# A64 register map
Vendor: Allwinner; Series: A64; File version: 0.1
CPU: CA53 0, little endian, MPU, no FPU, 0 interrupt priority bits
Registers are 32-bit, read-write, reset 0x0 unless marked. A register's access mark holds for its fields unless they carry their own. Offsets are from the block's base; [hi:lo] are bit positions; {n}, {i} and the like mark numbered series; 'fields as' and 'values as' point back to an identical list.

## AC (part 1 of 2)
Base 0x01C22C00
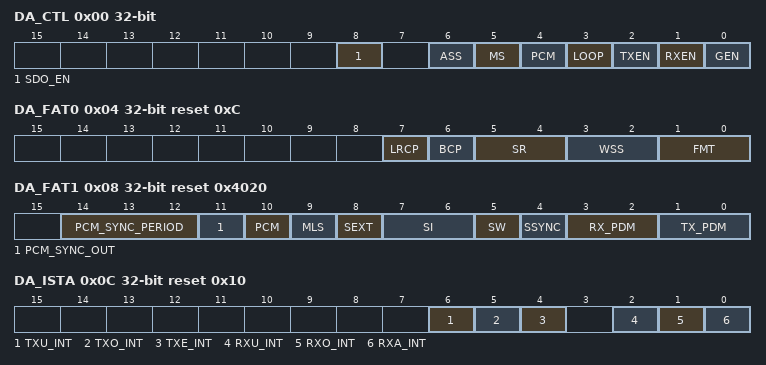
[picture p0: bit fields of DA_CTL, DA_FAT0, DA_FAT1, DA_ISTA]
0x00 DA_CTL — Digital Audio Control Register
  [8] SDO_EN — 0: Disable 1: Enable
    0=Disable; 1=Enable
  [6] ASS — Audio sample select when TX FIFO under run 0: Sending zero 1: Sending last audio sample
    0=Sending_zero; 1=Sending last audio sample
  [5] MS — Master Slave Select 0: Master 1: Slave
    0=Master; 1=Slave
  [4] PCM — 0: I2S Interface 1: PCM Interface
    0=I2S (I2S Interface); 1=PCM (PCM Interface)
  [3] LOOP — Loop back test 0: Normal mode 1: Loop back test When set `1`, connecting the SDO with the SDI in Master mode.
    0=Normal_mode; 1=Loop back test When set `1`, connecting the SDO with the SDI in Master mode
  [2] TXEN — Transmitter Block Enable 0: Disable 1: Enable
    0=Disable; 1=Enable
  [1] RXEN — Receiver Block Enable 0: Disable 1: Enable
    0=Disable; 1=Enable
  [0] GEN — Globe Enable A disable on this bit overrides any other block or channel enables and flushes all FIFOs. 0: Disable 1: Enable
    0=Disable; 1=Enable
0x04 DA_FAT0 reset 0xC — Digital Audio Format Register 0
  [7] LRCP — Left/ Right Clock Parity 0: Normal 1: Inverted In DSP/ PCM mode 0: MSB is available on 2nd BCLK rising edge after LRC rising edge 1: MSB is available on 1st BCLK rising edge after LRC rising edge
  [6] BCP — BCLK Parity 0: Normal 1: Inverted
    0=Normal; 1=Inverted
  [5:4] SR — Sample Resolution 00: 16-bits 01: 20-bits 10: 24-bits 11: Reserved
    0=_16_bits; 1=_20_bits; 2=_24_bits
  [3:2] WSS — Word Select Size 00: 16 BCLK 01: 20 BCLK 10: 24 BCLK 11: 32 BCLK
    0=16 BCLK; 1=20 BCLK; 2=24 BCLK; 3=32 BCLK
  [1:0] FMT — Serial Data Format 00: Standard I2S Format 01: Left Justified Format 10: Right Justified Format 11: Reserved
    0=Standard I2S Format; 1=Left Justified Format; 2=Right Justified Format
0x08 DA_FAT1 reset 0x4020 — Digital Audio Format Register 1
  [14:12] PCM_SYNC_PERIOD — PCM SYNC Period Clock Number 000: 16 BCLK period 001: 32 BCLK period 010: 64 BCLK period 011: 128 BCLK period 100: 256 BCLK period Others : Reserved
    0=16 BCLK period; 1=32 BCLK period; 2=64 BCLK period; 3=128 BCLK period; 4=256 BCLK period Others : Reserved
  [11] PCM_SYNC_OUT — PCM Sync Out 0: Enable PCM_SYNC output in Master mode 1: Suppress PCM_SYNC whilst keeping PCM_CLK running. Some Codec utilize this to enter a low power state.
    0=Enable PCM_SYNC output in Master mode; 1=Suppress PCM_SYNC whilst keeping PCM_CLK running. Some Codec utilize this to enter a low power state.
  [10] PCM — Out Mute Write 1 force PCM_OUT to 0
  [9] MLS — MSB / LSB First Select 0: MSB First 1: LSB First
    0=MSB (MSB First); 1=LSB (LSB First)
  [8] SEXT — Sign Extend (only for 16 bits slot) 0: Zeros or audio gain padding at LSB position 1: Sign extension at MSB position When writing the bit is 0, the unused bits are audio gain for 13-bit linear sample and zeros padding for 8-bit companding sample. When writing the bit is 1, the unused bits are both sign extension.
    0=Zeros or audio gain padding at LSB position; 1=Sign extension at MSB position When writing the bit is 0, the unused bits are audio gain for 13-bit linear sample and zeros padding for 8-bit companding sample. When writing the bit is 1, the unused bits are both sign extension.
  [7:6] SI — Slot Index 00: the 1st slot 01: the 2nd slot 10: the 3rd slot 11: the 4th slot
    0=_1st (the 1st slot); 1=_2nd (the 2nd slot); 2=_3rd (the 3rd slot); 3=_4th (the 4th slot)
  [5] SW — Slot Width 0: 8 clocks width 1: 16 clocks width Notes: For A-law or u-law PCM sample, if this bit is set to 1, eight zero bits are following with PCM sample.
    0=8 clocks width; 1=16 clocks width Notes: For A-law or u-law PCM sample, if this bit is set to 1, eight zero bits are following with PCM sample
  [4] SSYNC — Short Sync Select 0: Long Frame Sync 1: Short Frame Sync It should be set `1` for 8 clocks width slot.
    0=Long Frame Sync; 1=Short Frame Sync It should be set `1` for 8 clocks width slot
  [3:2] RX_PDM — PCM Data Mode 00: 16-bits Linear PCM 01: 8-bits Linear PCM 10: 8-bits u-law 11: 8-bits A-law
    0=16-bits Linear PCM; 1=8-bits Linear PCM; 2=_8_bits_ulaw; 3=_8_bits_Alaw
  [1:0] TX_PDM — PCM Data Mode 00: 16-bits Linear PCM 01: 8-bits Linear PCM 10: 8-bits u-law 11: 8-bits A-law
    values as RX_PDM
0x0C DA_ISTA reset 0x10 — Digital Audio Interrupt Status Register
  [6] TXU_INT — TX FIFO Under run Pending Interrupt 0: No Pending Interrupt 1: FIFO Under run Pending Interrupt
    0=No Pending Interrupt; 1=FIFO (FIFO Under run Pending Interrupt)
  [5] TXO_INT — TX FIFO Overrun Pending Interrupt 0: No Pending Interrupt 1: FIFO Overrun Pending Interrupt Write `1` to clear this interrupt
    0=No Pending Interrupt; 1=FIFO (FIFO Overrun Pending Interrupt Write `1` to clear this interrupt)
  [4] TXE_INT — TX FIFO Empty Pending Interrupt 0: No Pending IRQ 1: FIFO Empty Pending Interrupt Write `1` to clear this interrupt or automatic clear if interrupt condition fails.
    0=No Pending IRQ; 1=FIFO (FIFO Empty Pending Interrupt Write `1` to clear this interrupt or automatic clear if interrupt condition fails.)
  [2] RXU_INT — RX FIFO Under run Pending Interrupt 0: No Pending Interrupt 1:FIFO Under run Pending Interrupt Write 1 to clear this interrupt
    0=No Pending Interrupt 1:FIFO Under run Pending Interrupt Write 1 to clear this interrupt
  [1] RXO_INT — RX FIFO Overrun Pending Interrupt 0: No Pending IRQ 1: FIFO Overrun Pending IRQ Write `1` to clear this interrupt
    0=No Pending IRQ; 1=FIFO (FIFO Overrun Pending IRQ Write `1` to clear this interrupt)
  [0] RXA_INT — RX FIFO Data Available Pending Interrupt 0: No Pending IRQ 1: Data Available Pending IRQ Write `1` to clear this interrupt or automatic clear if interrupt condition fails.
    0=No Pending IRQ; 1=Data Available Pending IRQ Write `1` to clear this interrupt or automatic clear if interrupt condition fails
0x10 DA_RXFIFO — Digital Audio RX FIFO Register
  [31:0] RX_DATA ro — RX Sample Host can get one sample by reading this register. The left channel sample data is first and then the right channel sample.
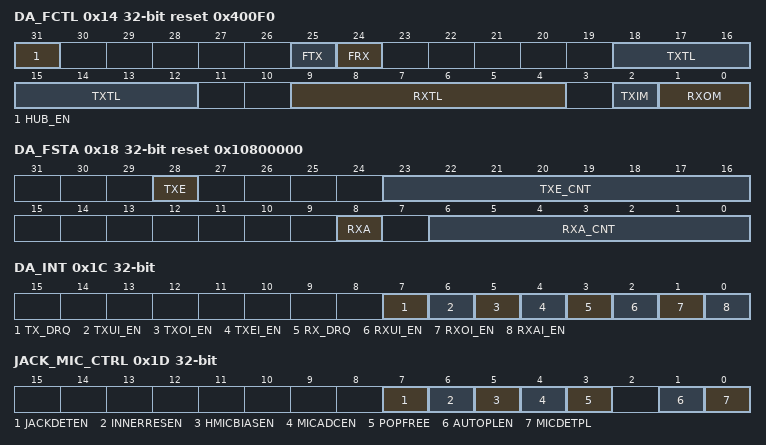
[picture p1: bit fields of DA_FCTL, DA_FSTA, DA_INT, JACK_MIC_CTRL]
0x14 DA_FCTL reset 0x400F0 — Digital Audio FIFO Control Register
  [31] HUB_EN — Audio Hub Enable 0: Disable 1: Enable
    0=Disable; 1=Enable
  [25] FTX — Write `1` to flush TX FIFO, self clear to `0`.
  [24] FRX — Write `1` to flush RX FIFO, self clear to `0`.
  [18:12] TXTL — TX FIFO Empty Trigger Level Interrupt and DMA request trigger level for TXFIFO normal condition Trigger Level = TXTL
  [9:4] RXTL — RX FIFO Trigger Level Interrupt and DMA request trigger level for RXFIFO normal condition Trigger Level = RXTL + 1
  [2] TXIM — TX FIFO Input Mode (Mode 0, 1) 0: Valid data at the MSB of TXFIFO register 1: Valid data at the LSB of TXFIFO register Example for 20-bits transmitted audio sample: Mode 0: FIFO_I[23:0] = {TXFIFO[31:12], 4`h0} Mode 1: FIFO_I[23:0] = {TXFIFO[19:0], 4`h0}
    0=Valid data at the MSB of TXFIFO register; 1=Valid data at the LSB of TXFIFO register Example for 20-bits transmitted audio sample: Mode 0: FIFO_I[23:0] = {TXFIFO[31:12], 4`h0} Mode 1: FIFO_I[23:0] = {TXFIFO[19:0], 4`h0}
  [1:0] RXOM — RX FIFO Output Mode (Mode 0, 1, 2, 3) 00: Expanding `0` at LSB of DA_RXFIFO register. 01: Expanding received sample sign bit at MSB of DA_RXFIFO register. 10: Truncating received samples at high half-word of DA_RXFIFO register and low half-word of DA_RXFIFO register is filled by `0`. 11: Truncating received samples at low half-word of DA_RXFIFO register and high half-word of DA_RXFIFO register is expanded by its sign bit. Example for 20-bits received audio sample: Mode 0: RXFIFO[31:0] = {FIFO_O[19:0], 12`h0} Mode 1: RXFIFO[31:0] = {12{FIFO_O[19]}, FIFO_O[19:0]} Mode 2: RXFIFO[31:0] = {FIFO_O[19:4], 16`h0} Mode 3: RXFIFO[31:0] = {16{FIFO_O[19], FIFO_O[19:4]}
    0=Expanding `0` at LSB of DA_RXFIFO register; 1=Expanding received sample sign bit at MSB of DA_RXFIFO register; 2=Truncating received samples at high half-word of DA_RXFIFO register and low half-word of DA_RXFIFO register is filled by `0`; 3=Truncating received samples at low half-word of DA_RXFIFO register and high half-word of DA_RXFIFO register is expanded by its sign bit. Example for 20-bits received audio sample: Mode 0: RXFIFO[31:0] = {FIFO_O[19:0], 12`h0} Mode 1: RXFIFO[31:0] = {12{FIFO_O[19]}, FIFO_O[19:0]} Mode 2: RXFIFO[31:0] = {FIFO_O[19:4], 16`h0} Mode 3: RXFIFO[31:0] = {16{FIFO_O[19], FIFO_O[19:4]}
0x18 DA_FSTA reset 0x10800000 — Digital Audio FIFO Status Register
  [28] TXE ro — TX FIFO Empty 0: No room for new sample in TX FIFO 1: More than one room for new sample in TX FIFO (>= 1 word)
    0=No room for new sample in TX FIFO; 1=More than one room for new sample in TX FIFO (>= 1 word)
  [23:16] TXE_CNT ro — TX FIFO Empty Space Word Counter
  [8] RXA ro — RX FIFO Available 0: No available data in RX FIFO 1: More than one sample in RX FIFO (>= 1 word)
    0=No available data in RX FIFO; 1=More than one sample in RX FIFO (>= 1 word)
  [6:0] RXA_CNT ro — RX FIFO Available Sample Word Counter
0x1C DA_INT — Digital Audio Interrupt Control Register
  [7] TX_DRQ — TX FIFO Empty DRQ Enable 0: Disable 1: Enable
    0=Disable; 1=Enable
  [6] TXUI_EN — TX FIFO Under run Interrupt Enable 0: Disable 1: Enable
    0=Disable; 1=Enable
  [5] TXOI_EN — TX FIFO Overrun Interrupt Enable 0: Disable 1: Enable When set to `1`, an interrupt happens when writing new audio data if TX FIFO is full.
    0=Disable; 1=Enable When set to `1`, an interrupt happens when writing new audio data if TX FIFO is full
  [4] TXEI_EN — TX FIFO Empty Interrupt Enable 0: Disable 1: Enable
    0=Disable; 1=Enable
  [3] RX_DRQ — RX FIFO Data Available DRQ Enable 0: Disable 1: Enable When set to `1`, RXFIFO DMA Request line is asserted if Data is available in RX FIFO.
    0=Disable; 1=Enable When set to `1`, RXFIFO DMA Request line is asserted if Data is available in RX FIFO
  [2] RXUI_EN — RX FIFO Under run Interrupt Enable 0: Disable 1: Enable
    0=Disable; 1=Enable
  [1] RXOI_EN — RX FIFO Overrun Interrupt Enable 0: Disable 1: Enable
    0=Disable; 1=Enable
  [0] RXAI_EN — RX FIFO Data Available Interrupt Enable 0: Disable 1: Enable
    0=Disable; 1=Enable
0x1D JACK_MIC_CTRL
  [7] JACKDETEN — Jack detect enable 0: disable, 1: enable
    0=disable, 1: enable
  [6] INNERRESEN — Inner 2.2k resistor between hbias and micdet enable 0: disable, 1: enable
    0=disable, 1: enable
  [5] HMICBIASEN — Handset Microphone Bias enable 0: disable, 1: enable
    0=disable, 1: enable
  [4] MICADCEN — Microphone detect ADC enable 0: disable, 1: enable
    0=disable, 1: enable
  [3] POPFREE — When this bit is 0, HBIAS MICADC is controlled by registor
  [1] AUTOPLEN — Enable the function to auto pull low micdet when jack removal 0: disable, 1: enable
    0=disable, 1: enable
  [0] MICDETPL — When this bit is 1and AUTOPLEN is 0, the micdet is pull to gnd
0x20 DA_TXFIFO — Digital Audio TX FIFO Register
  [31:0] TX_DATA wo — Transmitting left, right channel sample data should be written this register one by one. The left channel sample data is first and then the right channel sample.
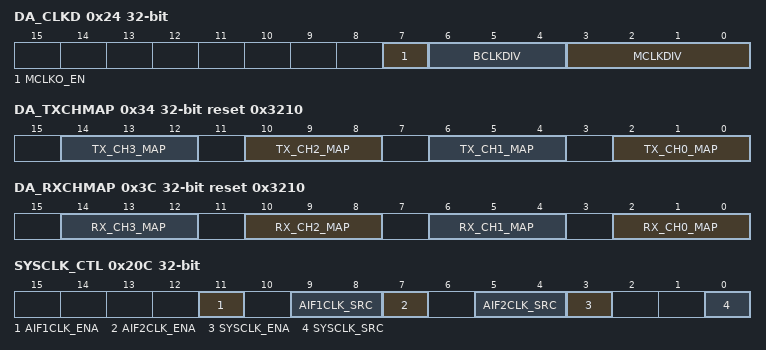
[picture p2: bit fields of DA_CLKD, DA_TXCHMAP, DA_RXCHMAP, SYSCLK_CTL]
0x24 DA_CLKD — Digital Audio Clock Divide Register
  [7] MCLKO_EN — 0: Disable MCLK Output 1: Enable MCLK Output Notes: Whether in Slave or Master mode, when this bit is set to 1, MCLK should be output.
    0=Disable MCLK Output; 1=Enable MCLK Output Notes: Whether in Slave or Master mode, when this bit is set to 1, MCLK should be output
  [6:4] BCLKDIV — BCLK Divide Ratio from MCLK 000: Divide by 2 (BCLK = MCLK/2) 001: Divide by 4 010: Divide by 6 011: Divide by 8 100: Divide by 12 101: Divide by 16 110: Divide by 32 111: Divide by 64
    0=Divide by 2 (BCLK = MCLK/2); 1=Divide_by_4; 2=Divide_by_6; 3=Divide_by_8; 4=Divide_by_12; 5=Divide_by_16; 6=Divide_by_32; 7=Divide_by_64
  [3:0] MCLKDIV — MCLK Divide Ratio from Audio PLL Output 0000: Divide by 1 0001: Divide by 2 0010: Divide by 4 0011: Divide by 6 0100: Divide by 8 0101: Divide by 12 0110: Divide by 16 0111: Divide by 24 1000: Divide by 32 1001: Divide by 48 1010: Divide by 64 Others : Reserved
    0=Divide_by_1; 1=Divide_by_2; 2=Divide_by_4; 3=Divide_by_6; 4=Divide_by_8; 5=Divide_by_12; 6=Divide_by_16; 7=Divide_by_24; 8=Divide_by_32; 9=Divide_by_48; 10=Divide by 64 Others : Reserved
0x28 DA_TXCNT — Digital Audio RX Sample Counter Register
  [31:0] TX_CNT — TX Sample Counter The audio sample number of sending into TXFIFO. When one sample is put into TXFIFO by DMA or by host IO, the TX sample counter register increases by one. The TX sample counter register can be set to any initial valve at any time. After been updated by the initial value, the counter register should count on base of this initial value.
0x2C DA_RXCNT — Digital Audio TX Sample Counter Register
  [31:0] RX_CNT — RX Sample Counter The audio sample number of writing into RXFIFO. When one sample is written by I2S_AP Engine, the RX sample counter register increases by one. The RX sample counter register can be set to any initial valve at any time. After been updated by the initial value, the counter register should count on base of this initial value.
0x30 DA_TXCHSEL reset 0x1 — Digital Audio TX Channel Select register
  [2:0] TX_CHSEL — TX Channel Select 0: 1-ch 1: 2-ch 2: 3-ch 3: 4-ch
    2=_3_minus_ch (3-ch); 3=_4_minus_ch (4-ch)
0x34 DA_TXCHMAP reset 0x3210 — Digital Audio TX Channel Mapping Register
  [all] fields
    {v}=_{v+1}_sample (v=0..3)
  [4n+2:4n] TX_CH{n}_MAP (n=0..3) — TX Channel{n} Mapping 000: 1 sample 001: 2 sample 010: 3 sample 011: 4 sample 1xx: Reserved
0x38 DA_RXCHSEL reset 0x1 — Digital Audio RX Channel Select register
  [2:0] RX_CHSEL — RX Channel Select 0: 1-ch 1: 2-ch 2: 3-ch 3: 4-ch Others: Reserved
    2=_3_minus_ch (3-ch); 3=_4_minus_ch (4-ch Others: Reserved)
0x3C DA_RXCHMAP reset 0x3210 — Digital Audio RX Channel Mapping Register
  [all] fields
    {v}=_{v+1}_sample (v=0..3)
  [4n+2:4n] RX_CH{n}_MAP (n=0..3) — RX Channel{n} Mapping 000: 1 sample 001: 2 sample 010: 3 sample 011: 4 sample 1xx: Reserved
0x200 Codec_RST reset not defined — Chip Soft Reset Register
0x20C SYSCLK_CTL — System Clock Control Register
  [11] AIF1CLK_ENA — AIF1CLK Enable 0: Disable 1: Enable
    0=Disable; 1=Enable
  [9:8] AIF1CLK_SRC — AIF1CLK Source Select 00: MLCK1 01: Reserved 1X: pll2_1x
    0=MLCK1; 2=pll2_1x
  [7] AIF2CLK_ENA — AIF2CLK Enable 0: Disable 1: Enable
    0=Disable; 1=Enable
  [5:4] AIF2CLK_SRC — AIF2CLK Source Select 00: MLCK1 01: Reserved 1X: pll2_1x
    0=MLCK1; 2=pll2_1x
  [3] SYSCLK_ENA — SYSCLK Enable 0: Disable 1: Enable
    0=Disable; 1=Enable
  [0] SYSCLK_SRC — System Clock Source Select 0: AIF1CLK 1: AIF2CLK
    0=AIF1CLK; 1=AIF2CLK
0x210 MOD_CLK_ENA — Module Clock Control Register
  [15:0] MODULE — Module clock enable control 0-Clock disable 1-Clock enable BIT15-AIF1 BIT14-AIF2 BIT13-AIF3 BIT12-Reserved BIT11-SRC1 BIT10-SRC2 BIT9-Reserved BIT8-Reserved BIT7-HPF & AGC BIT6-HPF & DRC0 BIT5-HPF & DRC1 BIT4-Reserved BIT3-ADC Digital BIT2-DAC Digital BIT1-Reserved BIT0-Reserved
0x214 MOD_RST_CTL — Module Reset Control Register
  [15:0] MODULE — Module reset control 0-Reset asserted 1-Reset de-asserted BIT15-AIF1 BIT14-AIF2 BIT13-AIF3 BIT12-Reserved BIT11-SRC1 BIT10-SRC2 BIT9-Reserved BIT8-Reserved BIT7-HPF & AGC BIT6-HPF & DRC0 BIT5-HPF & DRC1 BIT4-Reserved BIT3-ADC Digital BIT2-DAC Digital BIT1-Reserved BIT0-Reserved
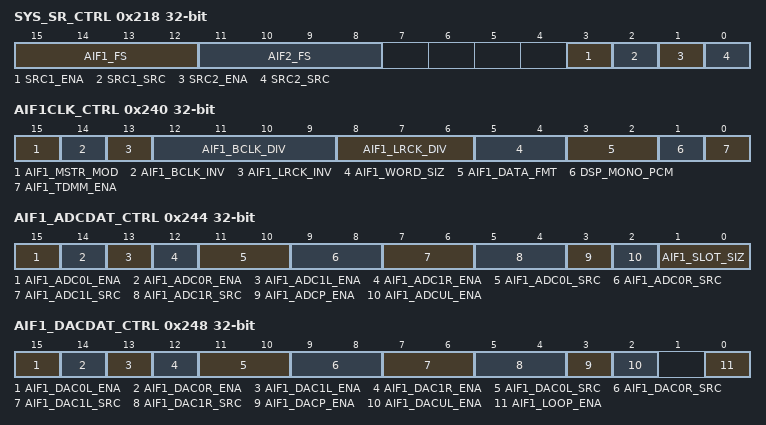
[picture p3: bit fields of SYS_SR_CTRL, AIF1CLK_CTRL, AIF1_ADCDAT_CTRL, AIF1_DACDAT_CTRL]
0x218 SYS_SR_CTRL — System Sample rate & SRC Configuration Register
  [15:12] AIF1_FS — AIF1 Sample Rate 0000: 8KHz 0001: 11.025KHz 0010: 12KHz 0011: 16KHz 0100: 22.05KHz 0101: 24KHz 0110: 32KHz 0111: 44.1KHz 1000: 48KHz 1001: 96KHz 1010: 192KHz Other: Reserved
    0=_8KHz; 1=_11_point_025KHz (11.025KHz); 2=_12KHz; 3=_16KHz; 4=_22_point_05KHz (22.05KHz); 5=_24KHz; 6=_32KHz; 7=_44_point_1KHz (44.1KHz); 8=_48KHz; 9=_96KHz; 10=192KHz Other: Reserved
  [11:8] AIF2_FS — AIF2 Sample Rate 0000: 8KHz 0001: 11.025KHz 0010: 12KHz 0011: 16KHz 0100: 22.05KHz 0101: 24KHz 0110: 32KHz 0111: 44.1KHz 1000: 48KHz 1001: 96KHz 1010: 192KHz Other: Reserved
    values as AIF1_FS
  [3] SRC1_ENA — SRC1 Enable. SRC1 Performs sample rate conversion of digital audio input to the codec. 0: Disable 1: Enable
    0=Disable; 1=Enable
  [2] SRC1_SRC — From which the input data will come. 0: AIF1 DAC Timeslot 0 1: AIF2 DAC
    0=AIF1 (AIF1 DAC Timeslot 0); 1=AIF2 (AIF2 DAC)
  [1] SRC2_ENA — SRC2 Enable. SRC2 Performs sample rate conversion of digital audio output from the codec. 0: Disable 1: Enable
    0=Disable; 1=Enable
  [0] SRC2_SRC — To which the converted data will be output. 0: AIF1 ADC Timeslot 0 1: AIF2 ADC
    0=AIF1 (AIF1 ADC Timeslot 0); 1=AIF2 (AIF2 ADC)
0x21C SYS_SRC_CLK — System SRC Clock Source Select Register
  [1:0] SRC_CLK_SLT — System SRC module output clock source select 00: normal mode 01: src1 output sample rate select DAC clk 10: src2 input sample rate select ADC clk 11: reserved
    0=normal_mode; 1=src1 output sample rate select DAC clk; 2=src2 input sample rate select ADC clk
0x220 SYS_DVC_CLK
  [1:0] AIFDVC_FS_SEL — 0 : DVC output to AIF sync 1 : normal
0x240 AIF1CLK_CTRL — AIF1 BCLK/LRCK Control Register
  [15] AIF1_MSTR_MOD — AIF1 Audio Interface mode select 0 = Master mode 1 = Slave mode
  [14] AIF1_BCLK_INV — AIF1 BCLK Polarity 0: Normal 1: Inverted
    0=Normal; 1=Inverted
  [13] AIF1_LRCK_INV — AIF1 LRCK Polarity 0: Normal 1: Inverted
    0=Normal; 1=Inverted
  [12:9] AIF1_BCLK_DIV — Select the AIF1CLK/BCLK1 ratio 0000: AIF1CLK/1 0001: AIF1CLK/2 0010: AIF1CLK/4 0011: AIF1CLK/6 0100: AIF1CLK/8 0101: AIF1CLK/12 0110: AIF1CLK/16 0111: AIF1CLK/24 1000: AIF1CLK/32 1001: AIF1CLK/48 1010: AIF1CLK/64 1011: AIF1CLK/96 1100: AIF1CLK/128 1101: AIF1CLK/192 1110: Reserved 1111: Reserved
    0=AIF1CLK_slash_1 (AIF1CLK/1); 1=AIF1CLK_slash_2 (AIF1CLK/2); 2=AIF1CLK_slash_4 (AIF1CLK/4); 3=AIF1CLK_slash_6 (AIF1CLK/6); 4=AIF1CLK_slash_8 (AIF1CLK/8); 5=AIF1CLK_slash_12 (AIF1CLK/12); 6=AIF1CLK_slash_16 (AIF1CLK/16); 7=AIF1CLK_slash_24 (AIF1CLK/24); 8=AIF1CLK_slash_32 (AIF1CLK/32); 9=AIF1CLK_slash_48 (AIF1CLK/48); 10=AIF1CLK_slash_64 (AIF1CLK/64); 11=AIF1CLK_slash_96 (AIF1CLK/96); 12=AIF1CLK_slash_128 (AIF1CLK/128); 13=AIF1CLK_slash_192 (AIF1CLK/192)
  [8:6] AIF1_LRCK_DIV — Select the BCLK1/LRCK ratio 000: 16 001: 32 010: 64 011: 128 100: 256 1xx: Reserved
    0=_16; 1=_32; 2=_64; 3=_128; 4=_256
  [5:4] AIF1_WORD_SIZ — AIF1 digital interface word size 00: 8bit 01: 16bit 10: 20bit 11: 24bit
    0=_8bit; 1=_16bit; 2=_20bit; 3=_24bit
  [3:2] AIF1_DATA_FMT — AIF1 digital interface data format 00: I2S mode 01: Left mode 10: Right mode 11: DSP mode
    0=I2S_mode; 1=Left_mode; 2=Right_mode; 3=DSP_mode
  [1] DSP_MONO_PCM — DSP Mono mode select 0: Stereo mode select 1: Mono mode select
    0=Stereo mode select; 1=Mono mode select
  [0] AIF1_TDMM_ENA — AIF1 TDM Mode enable 0: Disable 1: Enable
    0=Disable; 1=Enable
0x244 AIF1_ADCDAT_CTRL — AIF1 ADCDAT Control Register
  [15] AIF1_ADC0L_ENA — AIF1 ADC Timeslot 0 left channel enable 0: Disable 1: Enable
    0=Disable; 1=Enable
  [14] AIF1_ADC0R_ENA — AIF1 ADC Timeslot 0 right channel enable 0: Disable 1: Enable
    0=Disable; 1=Enable
  [13] AIF1_ADC1L_ENA — AIF1 ADC Timeslot 1 left channel enable 0: Disable 1: Enable
    0=Disable; 1=Enable
  [12] AIF1_ADC1R_ENA — AIF1 ADC Timeslot 1 right channel enable 0: Disable 1: Enable
    0=Disable; 1=Enable
  [11:10] AIF1_ADC0L_SRC — AIF1 ADC Timeslot 0 left channel data source select 00: AIF1 ADC0L 01: AIF1 ADC0R 10: (AIF1 ADC0L+AIF1 ADC0R) 11: (AIF1 ADC0L+AIF1 ADC0R)/2
  [9:8] AIF1_ADC0R_SRC — AIF1 ADC Timeslot 0 right channel data source select 00: AIF1 ADC0R 01: AIF1 ADC0L 10: (AIF1 ADC0L+AIF1 ADC0R) 11: (AIF1 ADC0L+AIF1 ADC0R)/2
  [7:6] AIF1_ADC1L_SRC — AIF1 ADC Timeslot 1 left channel data source select 00: AIF1 ADC1L 01: AIF1 ADC1R 10: (AIF1 ADC1L+AIF1 ADC1R) 11: (AIF1 ADC1L+AIF1 ADC1R)/2
  [5:4] AIF1_ADC1R_SRC — AIF1 ADC Timeslot 1 right channel data source select 00: AIF1 ADC1R 01: AIF1 ADC1L 10: (AIF1 ADC1L+AIF1 ADC1R) 11: (AIF1 ADC1L+AIF1 ADC1R)/2
  [3] AIF1_ADCP_ENA — AIF1 ADC Companding enable(8-bit mode only) 0: Disable 1: Enable
    0=Disable; 1=Enable
  [2] AIF1_ADCUL_ENA — AIF1 ADC Companding mode select 0: A-law 1: u-law
    0=Alaw; 1=ulaw
  [1:0] AIF1_SLOT_SIZ — Select the slot size(only in TDM mode) 00: 8 01: 16 10: 32 11: Reserved
    0=_8; 1=_16; 2=_32
0x248 AIF1_DACDAT_CTRL — AIF1 DACDAT Control Register
  [15] AIF1_DAC0L_ENA — AIF1 DAC Timeslot 0 left channel enable 0: Disable 1: Enable
    0=Disable; 1=Enable
  [14] AIF1_DAC0R_ENA — AIF1 DAC Timeslot 0 right channel enable 0: Disable 1: Enable
    0=Disable; 1=Enable
  [13] AIF1_DAC1L_ENA — AIF1 DAC Timeslot 1 left channel enable 0: Disable 1: Enable
    0=Disable; 1=Enable
  [12] AIF1_DAC1R_ENA — AIF1 DAC Timeslot 1 right channel enable 0: Disable 1: Enable
    0=Disable; 1=Enable
  [11:10] AIF1_DAC0L_SRC — AIF1 DAC Timeslot 0 left channel data source select 00: AIF1 DAC0L 01: AIF1 DA0R 10: (AIF1 DAC0L+AIF1 DAC0R) 11: (AIF1 DAC0L+AIF1 DAC0R)/2
  [9:8] AIF1_DAC0R_SRC — AIF1 DAC Timeslot 0 right channel data source select 00: AIF1 DAC0R 01: AIF1 DAC0L 10: (AIF1 DAC0L+AIF1 DAC0R) 11: (AIF1 DAC0L+AIF1 DAC0R)/2
  [7:6] AIF1_DAC1L_SRC — AIF1 DAC Timeslot 1 left channel data source select 00: AIF1 DAC1L 01: AIF1 DAC1R 10: (AIF1 DAC1L+AIF1 DAC1R) 11: (AIF1 DAC1L+AIF1 DAC1R)/2
  [5:4] AIF1_DAC1R_SRC — AIF1 DAC Timeslot 1 right channel data source select 00: AIF1 DAC1R 01: AIF1 DAC1L 10: (AIF1 DAC1L+AIF1 DAC1R) 11: (AIF1 DAC1L+AIF1 DAC1R)/2
  [3] AIF1_DACP_ENA — AIF1 DAC Companding enable(8-bit mode only) 00: Disable 01: Enable
  [2] AIF1_DACUL_ENA — AIF1 DAC Companding mode select 0: A-law 1: u-law
    0=Alaw; 1=ulaw
  [0] AIF1_LOOP_ENA — AIF1 loopback enable 0: No loopback 1: Loopback(ADCDAT1 data output to DACDAT1 data input)
    0=No_loopback; 1=Loopback_openingparen_ADCDAT1_data (Loopback(ADCDAT1 data output to DACDAT1 data input))
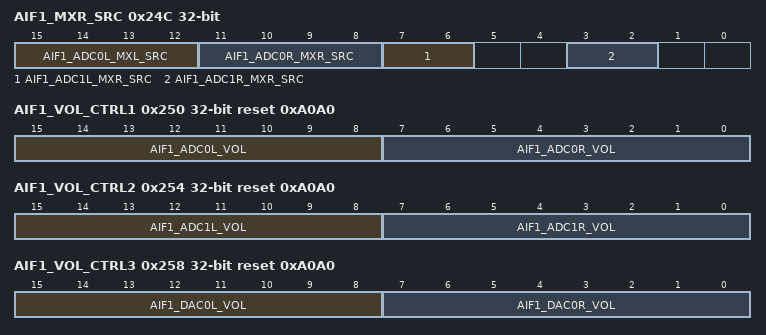
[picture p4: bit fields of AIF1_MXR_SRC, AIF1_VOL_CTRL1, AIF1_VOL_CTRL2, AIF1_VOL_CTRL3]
0x24C AIF1_MXR_SRC
  [15:12] AIF1_ADC0L_MXL_SRC — AIF1 ADC Timeslot 0 left channel mixer source select 0: Disable 1: Enable Bit15: AIF1 DAC0L data Bit14: AIF2 DACL data Bit13: ADCL data Bit12: AIF2 DACR data
  [11:8] AIF1_ADC0R_MXR_SRC — AIF1 ADC Timeslot 0 right channel mixer source select 0: Disable 1: Enable Bit11: AIF1 DAC0R data Bit10: AIF2 DACR data Bit9: ADCR data Bit8: AIF2 DACL data
  [7:6] AIF1_ADC1L_MXR_SRC — AIF1 ADC Timeslot 1 left channel mixer source select 0: Disable 1: Enable Bit7: AIF2 DACL data Bit6: ADCL data
  [3:2] AIF1_ADC1R_MXR_SRC — AIF1 ADC Timeslot 1 right channel mixer source select 0: Disable 1: Enable Bit3: AIF2 DACR data Bit2: ADCR data
0x250 AIF1_VOL_CTRL1 reset 0xA0A0 — AIF1 Volume Control 1 Register
  [15:8] AIF1_ADC0L_VOL — AIF1 ADC Timeslot 0 left channel volume (-119.25dB To 71.25dB, 0.75dB/Step) 0x00: Mute 0x01: -119.25dB ......... 0x9F = -0.75dB 0xA0 = 0dB 0xA1 = 0.75dB ......... 0xFF = 71.25dB
    0=Mute; 1=_minus_119_point_25dB (-119.25dB ......... 0x9F = -0.75dB 0xA0 = 0dB 0xA1 = 0.75dB ......... 0xFF = 71.25dB)
  [7:0] AIF1_ADC0R_VOL — AIF1 ADC Timeslot 0 right channel volume (-119.25dB To 71.25dB, 0.75dB/Step) 0x00: Mute 0x01: -119.25dB ......... 0x9F = -0.75dB 0xA0 = 0dB 0xA1 = 0.75dB ......... 0xFF = 71.25dB
    values as AIF1_ADC0L_VOL
0x254 AIF1_VOL_CTRL2 reset 0xA0A0 — AIF1 Volume Control 2 Register
  [15:8] AIF1_ADC1L_VOL — AIF1 ADC Timeslot 1 left channel volume (-119.25dB To 71.25dB, 0.75dB/Step) 0x00: Mute 0x01: -119.25dB ......... 0x9F = -0.75dB 0xA0 = 0dB 0xA1 = 0.75dB ......... 0xFF = 71.25dB
    values as AIF1_VOL_CTRL1.AIF1_ADC0L_VOL
  [7:0] AIF1_ADC1R_VOL — AIF1 ADC Timeslot 1 right channel volume (-119.25dB To 71.25dB, 0.75dB/Step) 0x00: Mute 0x01: -119.25dB ......... 0x9F = -0.75dB 0xA0 = 0dB 0xA1 = 0.75dB ......... 0xFF = 71.25dB
    values as AIF1_VOL_CTRL1.AIF1_ADC0L_VOL
0x258 AIF1_VOL_CTRL3 reset 0xA0A0 — AIF1 Volume Control 3 Register
  [15:8] AIF1_DAC0L_VOL — AIF1 DAC Timeslot 0 left channel volume (-119.25dB To 71.25dB, 0.75dB/Step) 0x00: Mute 0x01: -119.25dB ......... 0x9F = -0.75dB 0xA0 = 0dB 0xA1 = 0.75dB ......... 0xFF = 71.25dB
    values as AIF1_VOL_CTRL1.AIF1_ADC0L_VOL
  [7:0] AIF1_DAC0R_VOL — AIF1 DAC Timeslot 0 right channel volume (-119.25dB To 71.25dB, 0.75dB/Step) 0x00: Mute 0x01: -119.25dB ......... 0x9F = -0.75dB 0xA0 = 0dB 0xA1 = 0.75dB ......... 0xFF = 71.25dB
    values as AIF1_VOL_CTRL1.AIF1_ADC0L_VOL
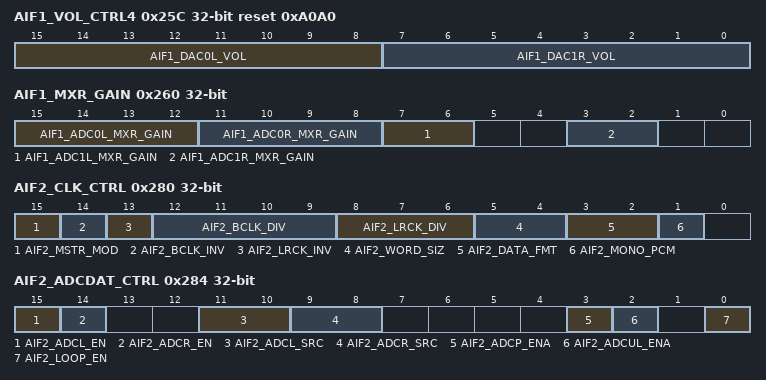
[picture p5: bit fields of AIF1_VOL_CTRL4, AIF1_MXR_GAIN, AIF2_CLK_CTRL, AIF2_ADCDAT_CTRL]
0x25C AIF1_VOL_CTRL4 reset 0xA0A0 — AIF1 Volume Control 4 Register
  [15:8] AIF1_DAC0L_VOL — AIF1 DAC Timeslot 0 left channel volume (-119.25dB To 71.25dB, 0.75dB/Step) 0x00: Mute 0x01: -119.25dB ......... 0x9F = -0.75dB 0xA0 = 0dB 0xA1 = 0.75dB ......... 0xFF = 71.25dB
    values as AIF1_VOL_CTRL1.AIF1_ADC0L_VOL
  [7:0] AIF1_DAC1R_VOL — AIF1 DAC Timeslot 1 right channel volume (-119.25dB To 71.25dB, 0.75dB/Step) 0x00: Mute 0x01: -119.25dB ......... 0x9F = -0.75dB 0xA0 = 0dB 0xA1 = 0.75dB ......... 0xFF = 71.25dB
    values as AIF1_VOL_CTRL1.AIF1_ADC0L_VOL
0x260 AIF1_MXR_GAIN — AIF1 Digital Mixer Gain Control Register
  [15:12] AIF1_ADC0L_MXR_GAIN — AIF1 ADC Timeslot 0 left channel mixer gain control 0: 0dB 1: -6dB Bit15: AIF1 DAC0L data Bit14: AIF2 DACL data Bit13: ADCL data Bit12: AIF2 DACR data
  [11:8] AIF1_ADC0R_MXR_GAIN — AIF1 ADC Timeslot 0 right channel mixer gain control 0: 0dB 1: -6dB Bit11: AIF1 DAC0R data Bit10: AIF2 DACR data Bit9: ADCR data Bit8: AIF2 DACL data
  [7:6] AIF1_ADC1L_MXR_GAIN — AIF1 ADC Timeslot 1 left channel mixer gain control 0: 0dB 1: -6dB Bit7: AIF2 DACL data Bit6: ADCL data
  [3:2] AIF1_ADC1R_MXR_GAIN — AIF1 ADC Timeslot 1 right channel mixer gain control 0: 0dB 1: -6dB Bit3: AIF2 DACR data Bit2: ADCR data
{0x224+0x40*i} AIF{i}_RXD_CTRL (i=1..3) — AIF{i} Receiver Data Discarding Control Register
  [15:8] AFTER — After data receiving progress begins, the first N-data will be discarded. N defined as follows: 0x00: None discarded 0x01: 1-data discarded ... 0xFF: 255-data discarded
    0=None discarded; 1=_1_minus_data (1-data discarded ...); 255=_255_minus_data (255-data discarded)
0x280 AIF2_CLK_CTRL — AIF2 BCLK/LRCK Control Register
  [15] AIF2_MSTR_MOD — AIF2 Audio Interface mode select 0 = Master mode 1 = Slave mode
  [14] AIF2_BCLK_INV — AIF2 BCLK Polarity 0: Normal 1: Inverted
    0=Normal; 1=Inverted
  [13] AIF2_LRCK_INV — AIF2 LRCK Polarity 0: Normal 1: Inverted
    0=Normal; 1=Inverted
  [12:9] AIF2_BCLK_DIV — Select the AIF2CLK/BCLK2 ratio 0000: AIF2CLK/1 0001: AIF2CLK/2 0010: AIF2CLK/4 0011: AIF2CLK/6 0100: AIF2CLK/8 0101: AIF2CLK/12 0110: AIF2CLK/16 0111: AIF2CLK/24 1000: AIF2CLK/32 1001: AIF2CLK/48 1010: AIF2CLK/64 1011: AIF2CLK/96 1100: AIF2CLK/128 1101: AIF2CLK/192 1110: Reserved 1111: Reserved
    0=AIF2CLK_slash_1 (AIF2CLK/1); 1=AIF2CLK_slash_2 (AIF2CLK/2); 2=AIF2CLK_slash_4 (AIF2CLK/4); 3=AIF2CLK_slash_6 (AIF2CLK/6); 4=AIF2CLK_slash_8 (AIF2CLK/8); 5=AIF2CLK_slash_12 (AIF2CLK/12); 6=AIF2CLK_slash_16 (AIF2CLK/16); 7=AIF2CLK_slash_24 (AIF2CLK/24); 8=AIF2CLK_slash_32 (AIF2CLK/32); 9=AIF2CLK_slash_48 (AIF2CLK/48); 10=AIF2CLK_slash_64 (AIF2CLK/64); 11=AIF2CLK_slash_96 (AIF2CLK/96); 12=AIF2CLK_slash_128 (AIF2CLK/128); 13=AIF2CLK_slash_192 (AIF2CLK/192)
  [8:6] AIF2_LRCK_DIV — Select the BCLK2/LRCK2 ratio 000: 16 001: 32 010: 64 011: 128 100: 256 1xx: Reserved
    0=_16; 1=_32; 2=_64; 3=_128; 4=_256
  [5:4] AIF2_WORD_SIZ — AIF2 digital interface world length 00: 8bit 01: 16bit 10: 20bit 11: 24bit
    0=_8bit; 1=_16bit; 2=_20bit; 3=_24bit
  [3:2] AIF2_DATA_FMT — AIF digital interface data format 00: I2S mode 01: Left mode 10: Right mode 11: DSP mode
    0=I2S_mode; 1=Left_mode; 2=Right_mode; 3=DSP_mode
  [1] AIF2_MONO_PCM — AIF2 Mono PCM mode select 0: Stereo mode select 1: Mono mode select
    0=Stereo mode select; 1=Mono mode select
0x284 AIF2_ADCDAT_CTRL — AIF2 ADCDAT Control Register
  [15] AIF2_ADCL_EN — AIF2 ADC left channel enable 0: Disable 1: Enable
    0=Disable; 1=Enable
  [14] AIF2_ADCR_EN — AIF2 ADC right channel enable 0: Disable 1: Enable
    0=Disable; 1=Enable
  [11:10] AIF2_ADCL_SRC — AIF2 ADC left channel data source select 00: AIF2 ADCL 01: AIF2 ADCR 10: (AIF2 ADCL+AIF2 ADCR) 11: (AIF2 ADCL+AIF2 ADCR)/2
  [9:8] AIF2_ADCR_SRC — AIF2 ADC right channel data source select 00: AIF2 ADCR 01: AIF2 ADCL 10: (AIF2 ADCL+AIF2 ADCR) 11: (AIF2 ADCL+AIF2 ADCR)/2
  [3] AIF2_ADCP_ENA — AIF2 ADC Companding enable(8-bit mode only) 00: Disable 01: Enable
  [2] AIF2_ADCUL_ENA — AIF2 ADC Companding mode select 0: A-law 1: u-law
    0=Alaw; 1=ulaw
  [0] AIF2_LOOP_EN — AIF2 loopback enable 0: No loopback 1: Loopback(ADCDAT2 data output to DACDAT2 data input)
    0=No_loopback; 1=Loopback_openingparen_ADCDAT2_data (Loopback(ADCDAT2 data output to DACDAT2 data input))
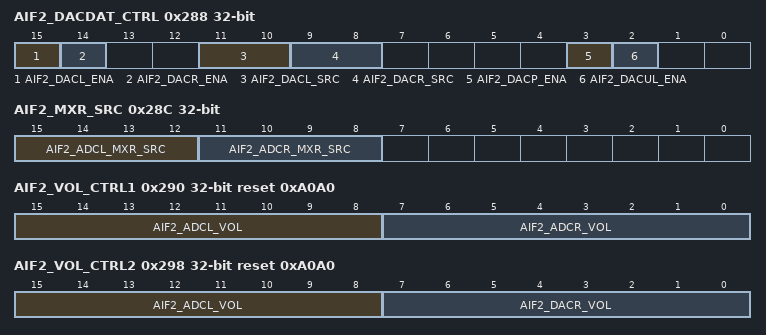
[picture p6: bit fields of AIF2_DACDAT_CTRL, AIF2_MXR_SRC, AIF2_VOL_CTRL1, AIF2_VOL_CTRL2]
0x288 AIF2_DACDAT_CTRL — AIF2 DACDAT Control Register
  [15] AIF2_DACL_ENA — AIF2 DAC left channel enable 0: Disable 1: Enable
    0=Disable; 1=Enable
  [14] AIF2_DACR_ENA — AIF2 DAC right channel enable 0: Disable 1: Enable
    0=Disable; 1=Enable
  [11:10] AIF2_DACL_SRC — AIF2 DAC left channel data source select 00: AIF2 DACL 01: AIF2 DACR 10: (AIF2 DACL+AIF2 DACR) 11: (AIF2 DACL+AIF2 DACR)/2
  [9:8] AIF2_DACR_SRC — AIF2 DAC right channel data source select 00: AIF2 DACR 01: AIF2 DACL 10: (AIF2 DACL+AIF2 DACR) 11: (AIF2 DACL+AIF2 DACR)/2
  [3] AIF2_DACP_ENA — AIF2 DAC Companding enable(8-bit mode only) 00: Disable 01: Enable
  [2] AIF2_DACUL_ENA — AIF2 DAC Companding mode select 0: A-law 1: u-law
    0=Alaw; 1=ulaw
0x28C AIF2_MXR_SRC — AIF2 Digital Mixer Source Select Register
  [15:12] AIF2_ADCL_MXR_SRC — AIF2 ADC left channel mixer source select 0: Disable 1:Enable Bit15: AIF1 DAC0L data Bit14: AIF1 DAC1L data Bit13: AIF2 DACR data Bit12: ADCL data
  [11:8] AIF2_ADCR_MXR_SRC — AIF2 ADC right channel mixer source select 0: Disable 1:Enable Bit11: AIF1 DA0R data Bit10: AIF1 DA1R data Bit9: AIF2 DACL data Bit8: ADCR data
0x290 AIF2_VOL_CTRL1 reset 0xA0A0 — AIF2 Volume Control 1 Register
  [15:8] AIF2_ADCL_VOL — AIF2 ADC left channel volume (-119.25dB To 71.25dB, 0.75dB/Step) 0x00: Mute 0x01: -119.25dB ......... 0x9F = -0.75dB 0xA0 = 0dB 0xA1 = 0.75dB ......... 0xFF = 71.25dB
    values as AIF1_VOL_CTRL1.AIF1_ADC0L_VOL
  [7:0] AIF2_ADCR_VOL — AIF2 ADC right channel volume (-119.25dB To 71.25dB, 0.75dB/Step) 0x00: Mute 0x01: -119.25dB ......... 0x9F = -0.75dB 0xA0 = 0dB 0xA1 = 0.75dB ......... 0xFF = 71.25dB
    values as AIF1_VOL_CTRL1.AIF1_ADC0L_VOL
0x298 AIF2_VOL_CTRL2 reset 0xA0A0 — AIF2 Volume Control 2 Register
  [15:8] AIF2_ADCL_VOL — AIF2 ADC left channel volume (-119.25dB To 71.25dB, 0.75dB/Step) 0x00: Mute 0x01: -119.25dB ......... 0x9F = -0.75dB 0xA0 = 0dB 0xA1 = 0.75dB ......... 0xFF = 71.25dB
    values as AIF1_VOL_CTRL1.AIF1_ADC0L_VOL
  [7:0] AIF2_DACR_VOL — AIF2 DAC right channel volume (-119.25dB To 71.25dB, 0.75dB/Step) 0x00: Mute 0x01: -119.25dB ......... 0x9F = -0.75dB 0xA0 = 0dB 0xA1 = 0.75dB ......... 0xFF = 71.25dB
    values as AIF1_VOL_CTRL1.AIF1_ADC0L_VOL
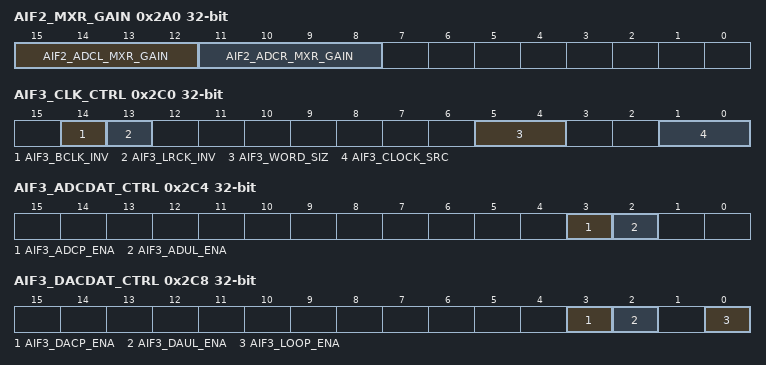
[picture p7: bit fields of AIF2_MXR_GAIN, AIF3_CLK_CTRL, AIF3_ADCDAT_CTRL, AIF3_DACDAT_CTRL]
0x2A0 AIF2_MXR_GAIN — AIF2 Digital Mixer Gain Control Register
  [15:12] AIF2_ADCL_MXR_GAIN — AIF2 ADC left channel mixer gain control 0: 0dB 1: -6dB Bit15: AIF1 DAC0L data Bit14: AIF1 DAC1L data Bit13: AIF2 DACR data Bit12: ADCL data
  [11:8] AIF2_ADCR_MXR_GAIN — AIF2 ADC right channel mixer gain control 0: 0dB 1: -6dB Bit11: AIF1 DAC0R data Bit10: AIF1 DAC1R data Bit9: AIF2 DACL data Bit8: ADCR data
0x2C0 AIF3_CLK_CTRL — AIF3 BCLK/LRCK Control Register
  [14] AIF3_BCLK_INV — AIF3 BCLK Polarity 0: Normal 1: Inverted
    0=Normal; 1=Inverted
  [13] AIF3_LRCK_INV — AIF3 LRCK Polarity 0: Normal 1: Inverted
    0=Normal; 1=Inverted
  [5:4] AIF3_WORD_SIZ — AIF3 digital interface world length 00: 8bit 01: 16bit 10: 20bit 11: 24bit
    0=_8bit; 1=_16bit; 2=_20bit; 3=_24bit
  [1:0] AIF3_CLOCK_SRC — AIF3 BCLK/LRCK source control 0: BCLK/LRCK Come from AIF1 1: BCLK/LRCK Come from AIF2 2: BCLK/LRCK is generated by AIF3, and the source clock is AIF1CLK 3: Reserved
    2=generated_by (BCLK/LRCK is generated by AIF3, and the source clock is AIF1CLK)
0x2C4 AIF3_ADCDAT_CTRL — AIF3 ADCDAT Control Register
  [3] AIF3_ADCP_ENA — AIF3 ADC Companding enable 00: Disable 01: Enable
  [2] AIF3_ADUL_ENA — AIF3 ADC Companding mode select 0: A-law 1: u-law
    0=Alaw; 1=ulaw
0x2C8 AIF3_DACDAT_CTRL — AIF3 DACDAT Control Register
  [3] AIF3_DACP_ENA — AIF3 DAC Companding enable(8-bit mode only) 00: Disable 01: Enable
  [2] AIF3_DAUL_ENA — AIF3 DAC Companding mode select 00: u-law 01: A-law
  [0] AIF3_LOOP_ENA — AIF3 loopback enable 0: No loopback 1: Loopback(ADCDAT3 data output to DACDAT3 data input)
    0=No_loopback; 1=Loopback_openingparen_ADCDAT3_data (Loopback(ADCDAT3 data output to DACDAT3 data input))
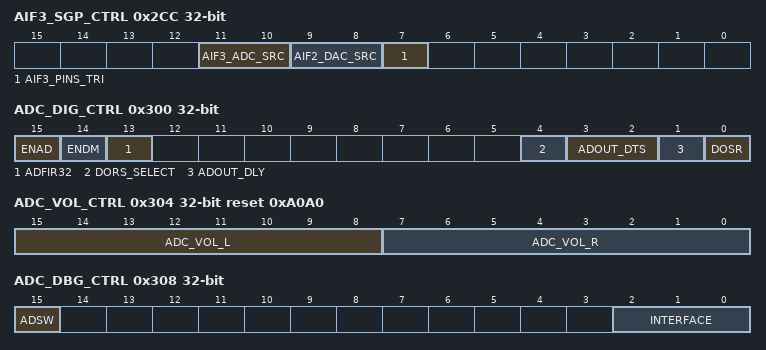
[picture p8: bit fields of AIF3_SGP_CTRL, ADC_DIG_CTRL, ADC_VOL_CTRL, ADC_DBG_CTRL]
0x2CC AIF3_SGP_CTRL — AIF3 Signal Path Control Register
  [11:10] AIF3_ADC_SRC — AIF3 PCM output source select 00: None 01: AIF2 ADC left channel 10: AIF2 ADC right channel 11: Reserved
  [9:8] AIF2_DAC_SRC — AIF2 DAC input source select 00: Left and right inputs from AIF2 01: Left input from AIF3; Right input from AIF2 10: Left input from AIF2; Right input from AIF3 11: Reserved
    0=Left and right inputs from AIF2; 1=Left input from AIF3; Right input from AIF2; 2=Left input from AIF2; Right input from AIF3
  [7] AIF3_PINS_TRI — AIF3 Pins Tri-state Control 0 = AIF3 pins operate normally 1 = Tri-state all AIF3 interface pins
0x300 ADC_DIG_CTRL — ADC Digital Control Register
  [15] ENAD — ADC Digital part enable 0: Disable 1: Enable
    0=Disable; 1=Enable
  [14] ENDM — Digital microphone enable 0: Analog ADC mode 1:
    0=Analog ADC mode; 1=0b1
  [13] ADFIR32 — Enable 32-tap FIR filter 0: 64-tap 1: 32-tap
    0=_64_minus_tap (64-tap); 1=_32_minus_tap (32-tap)
  [4] DORS_SELECT — Digital Microphone Oversample Rate Select 0 128fs 1 64fs
  [3:2] ADOUT_DTS — ADC Delay Time For transmitting data after ENAD 00:5ms 01:10ms 10:20ms 11:30ms
  [1] ADOUT_DLY — ADC Delay Function enable for transmitting data after ENAD 0: Disable 1: Enable
    0=Disable; 1=Enable
  [0] DOSR — Digital Microphone Oversampling Rate 0:64 fs 1:128fs
0x304 ADC_VOL_CTRL reset 0xA0A0 — ADC Volume Control Register
  [15:8] ADC_VOL_L — ADC left channel volume (-119.25dB To 71.25dB, 0.75dB/Step) 0x00: Mute 0x01: -119.25dB ......... 0x9F = -0.75dB 0xA0 = 0dB 0xA1 = 0.75dB ......... 0xFF = 71.25dB
    values as AIF1_VOL_CTRL1.AIF1_ADC0L_VOL
  [7:0] ADC_VOL_R — ADC left channel volume (-119.25dB To 71.25dB, 0.75dB/Step) 0x00: Mute 0x01: -119.25dB ......... 0x9F = -0.75dB 0xA0 = 0dB 0xA1 = 0.75dB ......... 0xFF = 71.25dB
    values as AIF1_VOL_CTRL1.AIF1_ADC0L_VOL
0x308 ADC_DBG_CTRL — ADC Debug Control Register
  [15] ADSW — ADC input channel swap enable 0: Disable 1: Enable
    0=Disable; 1=Enable
  [2:0] INTERFACE — Interface between ADDA digital part and ADDA analog part debug control. Normal Normal BCLK2/LRCK2/ADCDAT2/DACDAT2 BCLK3/LRCK3/ADCDAT3/DACDAT3 is multiplexed as follows: BCLK2 CKAD_A input to ADC analog part LRCK2 Normal ADCDAT2 ADIN_L[1] output from ADC analog part DACDAT2 ADIN_L[0] output from ADC analog part BCLK3 CKAD_A output from ADC digital part LRCK3 Normal ADCDAT3 ADIN_L/R[1] input to ADC digital part DACDAT3 ADIN_L/R[0] input to ADC digital part BCLK2/LRCK2/ADADAT2/DACDAT2 BCLK3/LRCK3/ADCDAT3/DACDAT3 is multiplexed as follows: BCLK2 CKAD_A input to ADC analog part LRCK2 Normal ADCDAT2 ADIN_R[1] output from ADC analog part DACDAT2 ADIN_R[0] output from ADC analog part BCLK3 CKAD_A output from ADC digital part LRCK3 Normal ADCDAT3 ADIN_L/R[1] input to ADC digital part DACDAT3 ADIN_L/R[0] input to ADC digital part BCLK2/LRCK2/ADADAT2/DACDAT2 BCLK3/LRCK3/ADCDAT3/DACDAT3 is multiplexed as follows: BCLK2 CKDA_A output from DAC digital part LRCK2 DAOUT_L[6] output from DAC digital part ADCDAT2 DAOUT_L[5] output from DAC digital part DACDAT2 DAOUT_L[4] output from DAC digital part BCLK3 DAOUT_L[3] output from DAC digital part LRCK3 DAOUT_L[2] output from DAC digital part ADCDAT3 DAOUT_L[1] output from DAC digital part DACDAT3 DAOUT_L[0] output from DAC digital part BCLK2/LRCK2/ADADAT2/DACDAT2 BCLK3/LRCK3/ADCDAT3/DACDAT3 is multiplexed as follows: BCLK2 CKDA_A output from DAC digital part LRCK2 DAOUT_R[6] output from DAC digital part ADCDAT2 DAOUT_R[5] output from DAC digital part DACDAT2 DAOUT_R[4] output from DAC digital part BCLK3 DAOUT_R[3] output from DAC digital part LRCK3 DAOUT_R[2] output from DAC digital part ADCDAT3 DAOUT_R[1] output from DAC digital part DACDAT3 DAOUT_R[0] output from DAC digital part BCLK2/LRCK2/ADADAT2/DACDAT2 BCLK3/LRCK3/ADCDAT3/DACDAT3 is multiplexed as follows: BCLK2 CKDA_A input to DAC analog part LRCK2 DAOUT_L/R[6] input to DAC analog part ADCDAT2 DAOUT_L/R[5] input to DAC analog part DACDAT2 DAOUT_L/R[4] input to DAC analog part BCLK3 DAOUT_L/R[3] input to DAC analog part LRCK3 DAOUT_L/R[2] input to DAC analog part ADCDAT3 DAOUT_L/R[1] input to DAC analog part DACDAT3 DAOUT_L/R[0] input to DAC analog part BCLK2/LRCK2/ADADAT2/DACDAT2 BCLK3/LRCK3/ADCDAT3/DACDAT3 is multiplexed as follows: BCLK2 CKDA_A input to DAC analog part LRCK2 DAOUT_L/R[6] input to DAC analog part ADCDAT2 DAOUT_L/R[5] input to DAC analog part DACDAT2 DAOUT_L/R[4] input to DAC analog part BCLK3 DAOUT_L/R[3] input to DAC analog part LRCK3 DAOUT_L/R[2] input to DAC analog part ADCDAT3 DAOUT_L/R[1] input to DAC analog part DACDAT3 DAOUT_L/R[0] input to DAC analog part
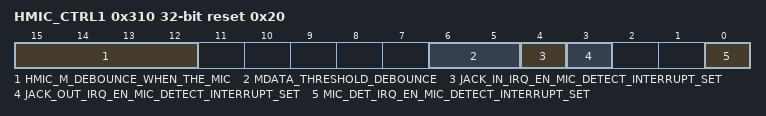
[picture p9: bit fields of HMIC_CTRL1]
0x310 HMIC_CTRL1 reset 0x20 — HMIC Control 1 Register
  [15:12] HMIC_M_DEBOUNCE_WHEN_THE_MIC — HMIC_M Debounce when the MIC Key down or up.
  [6:5] MDATA_THRESHOLD_DEBOUNCE — MDATA_Threshold_Debounce 00:0 01:1 10:2 11: Reserve(default 1)
    3=Reserve_openingparen_default (Reserve(default 1))
  [4] JACK_IN_IRQ_EN_MIC_DETECT_INTERRUPT_SET — JACK_IN_IRQ_EN MIC Detect Interrupt Set 0 : disable 1 : enable
  [3] JACK_OUT_IRQ_EN_MIC_DETECT_INTERRUPT_SET — JACK_OUT_IRQ_EN MIC Detect Interrupt Set 0 : disable 1 : enable
  [0] MIC_DET_IRQ_EN_MIC_DETECT_INTERRUPT_SET — MIC_DET_IRQ_EN MIC Detect Interrupt Set 0:disable 1:enable
